# CMS32L051 register map
Vendor: CMS; Series: CMS32L051; File version: 1.2
CPU: CM0+ r0p1, little endian, no MPU, no FPU, VTOR, 2 interrupt priority bits
Registers are 8-bit, read-write, reset 0x0 unless marked. A register's access mark holds for its fields unless they carry their own. Offsets are from the block's base; [hi:lo] are bit positions; {n}, {i} and the like mark numbered series; 'fields as' and 'values as' point back to an identical list.

## TM41 — General Purpose Timer 4
Base 0x40042180
{0x0+2i} TCR1{i} (i=0..3) 16-bit ro reset 0xFFFF — Timer count register 0{i}
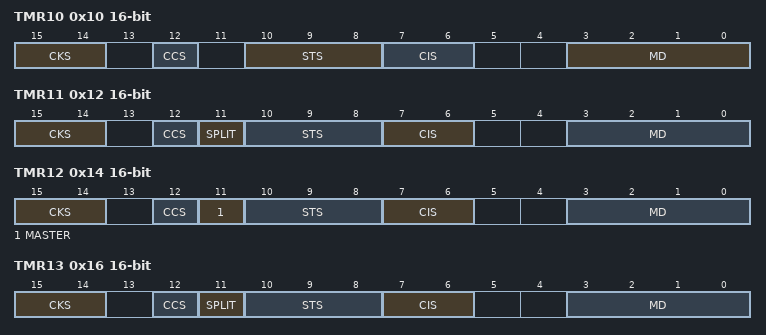
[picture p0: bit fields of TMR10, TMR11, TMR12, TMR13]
0x10 TMR10 16-bit — Timer mode register mn
  [15:14] CKS — Selection of operation clock (fMCK) of channel n
  [12] CCS — Selection of count clock (fTCLK) of channel n
  [10:8] STS — Setting of start trigger or capture trigger of channel n
  [7:6] CIS — Selection of TImn pin input valid edge
  [3:0] MD — Operation mode of channel n
0x12 TMR11 16-bit — Timer mode register mn
  [15:14] CKS — Selection of operation clock (fMCK) of channel n
  [12] CCS — Selection of count clock (fTCLK) of channel n
  [11] SPLIT — Selection of 8 or 16-bit timer operation for channels 1 and 3
  [10:8] STS — Setting of start trigger or capture trigger of channel n
  [7:6] CIS — Selection of TImn pin input valid edge
  [3:0] MD — Operation mode of channel n
0x14 TMR12 16-bit — Timer mode register mn
  [15:14] CKS — Selection of operation clock (fMCK) of channel n
  [12] CCS — Selection of count clock (fTCLK) of channel n
  [11] MASTER — Selection between using channel n independently or simultaneously with another channel (as a slave or master)
  [10:8] STS — Setting of start trigger or capture trigger of channel n
  [7:6] CIS — Selection of TImn pin input valid edge
  [3:0] MD — Operation mode of channel n
0x16 TMR13 16-bit — Timer mode register mn
  fields as TMR11
{0xC+2i} TSR{i} 16-bit ro (i=10..13) — Timer status register mn
  [0] OVF — Counter overflow status of channel n
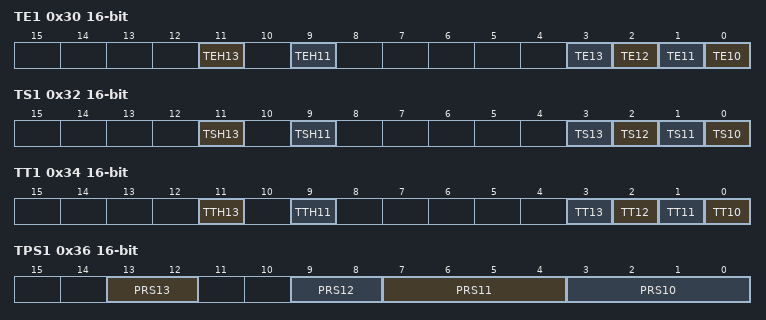
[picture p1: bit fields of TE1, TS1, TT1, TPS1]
0x30 TE1 16-bit ro — Timer channel enable status register m
  [11] TEH13 — Indication of whether operation of the higher 8-bit timer is enabled or stopped when channel 3 is in the 8-bit timer mode
  [9] TEH11 — Indication of whether operation of the higher 8-bit timer is enabled or stopped when channel 1 is in the 8-bit timer mode
  [n-10] TE{n} (n=10..13) — Indication of operation enable/stop status of channel {n-10}
0x32 TS1 16-bit — Timer channel start register 0
  [11] TSH13 — Trigger to enable operation (start operation) of the higher 8-bit timer when channel 3 is in the 8-bit timer mode
  [9] TSH11 — Trigger to enable operation (start operation) of the higher 8-bit timer when channel 1 is in the 8-bit timer mode
  [n-10] TS{n} (n=10..13) — Operation enable (start) trigger of channel {n-10}
0x34 TT1 16-bit — Timer channel stop register 0
  [11] TTH13 — Trigger to stop operation of the higher 8-bit timer when channel 3 is in the 8-bit timer mode
  [9] TTH11 — Trigger to stop operation of the higher 8-bit timer when channel 1 is in the 8-bit timer mode
  [n-10] TT{n} (n=10..13) — Operation stop trigger of channel {n-10}
0x36 TPS1 16-bit — Timer clock select register 0
  [13:12] PRS13 — Prescaler 3
  [9:8] PRS12 — Prescaler 2
  [7:4] PRS11 — Prescaler 1
  [3:0] PRS10 — Prescaler 0
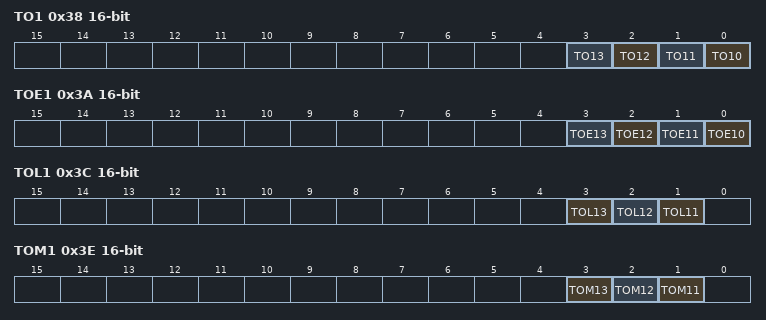
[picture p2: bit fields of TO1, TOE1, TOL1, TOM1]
0x38 TO1 16-bit — Timer output register 0
  [n-10] TO{n} (n=10..13) — Timer output of channel {n-10}
0x3A TOE1 16-bit — Timer output enable register 0
  [n-10] TOE{n} (n=10..13) — Timer output enable of channel {n-10}
0x3C TOL1 16-bit — Timer output level register 0
  [3] TOL13 — Control of timer output level of channel 3
  [2] TOL12 — Control of timer output level of channel 2
  [1] TOL11 — Control of timer output level of channel 1
0x3E TOM1 16-bit — Timer output mode register 0
  [3] TOM13 — Control of timer output mode of channel 3
  [2] TOM12 — Control of timer output mode of channel 2
  [1] TOM11 — Control of timer output mode of channel 1
{0x198+2i} TDR1{i} (i=0..1) 16-bit — Timer data register 0{i}
0x19A TDR11L (alternate view of TDR11) — Timer data lower register 01
0x19B TDR11H (alternate view of TDR11) — Timer data higher register 01
{0x1E0+2i} TDR1{i} (i=2..3) 16-bit — Timer data register 0{i}
0x1E6 TDR13L (alternate view of TDR13) — Timer data lower register 03
0x1E7 TDR13H (alternate view of TDR13) — Timer data higher register 03

## Notices in the file
Copyright (C) 2012-2014 ARM Limited. All rights reserved.
Purpose: System Viewer Description (SVD) Example (Schema Version 1.1)
This is a description of a none-existent and incomplete device
for demonstration purposes only.
Redistribution and use in source and binary forms, with or without
modification, are permitted provided that the following conditions are met:
- Redistributions of source code must retain the above copyright
notice, this list of conditions and the following disclaimer.
- Redistributions in binary form must reproduce the above copyright
notice, this list of conditions and the following disclaimer in the
documentation and/or other materials provided with the distribution.
- Neither the name of ARM nor the names of its contributors may be used
to endorse or promote products derived from this software without
specific prior written permission.
THIS SOFTWARE IS PROVIDED BY THE COPYRIGHT HOLDERS AND CONTRIBUTORS "AS IS"
AND ANY EXPRESS OR IMPLIED WARRANTIES, INCLUDING, BUT NOT LIMITED TO, THE
IMPLIED WARRANTIES OF MERCHANTABILITY AND FITNESS FOR A PARTICULAR PURPOSE
ARE DISCLAIMED. IN NO EVENT SHALL COPYRIGHT HOLDERS AND CONTRIBUTORS BE
LIABLE FOR ANY DIRECT, INDIRECT, INCIDENTAL, SPECIAL, EXEMPLARY, OR
CONSEQUENTIAL DAMAGES (INCLUDING, BUT NOT LIMITED TO, PROCUREMENT OF
SUBSTITUTE GOODS OR SERVICES; LOSS OF USE, DATA, OR PROFITS; OR BUSINESS
INTERRUPTION) HOWEVER CAUSED AND ON ANY THEORY OF LIABILITY, WHETHER IN
CONTRACT, STRICT LIABILITY, OR TORT (INCLUDING NEGLIGENCE OR OTHERWISE)
ARISING IN ANY WAY OUT OF THE USE OF THIS SOFTWARE, EVEN IF ADVISED OF THE
POSSIBILITY OF SUCH DAMAGE.
